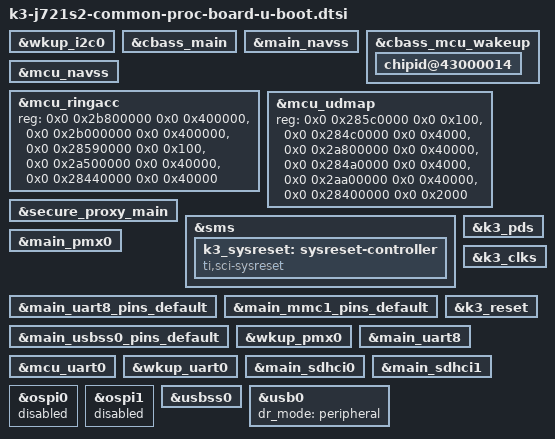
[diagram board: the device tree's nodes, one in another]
// SPDX-License-Identifier: GPL-2.0
/*
 * Copyright (C) 2021-2023 Texas Instruments Incorporated - https://www.ti.com/
 */

#include "k3-j721s2-binman.dtsi"

&wkup_i2c0 {
	bootph-pre-ram;
};

&cbass_main {
	bootph-pre-ram;
};

&main_navss {
	bootph-pre-ram;
};

&cbass_mcu_wakeup {
	bootph-pre-ram;

	chipid@43000014 {
		bootph-pre-ram;
	};
};

&mcu_navss {
	bootph-pre-ram;
};

&mcu_ringacc {
	reg =   <0x0 0x2b800000 0x0 0x400000>,
		<0x0 0x2b000000 0x0 0x400000>,
		<0x0 0x28590000 0x0 0x100>,
		<0x0 0x2a500000 0x0 0x40000>,
		<0x0 0x28440000 0x0 0x40000>;
	reg-names = "rt", "fifos", "proxy_gcfg", "proxy_target", "cfg";
	bootph-pre-ram;
};

&mcu_udmap {
	reg =   <0x0 0x285c0000 0x0 0x100>,
		<0x0 0x284c0000 0x0 0x4000>,
		<0x0 0x2a800000 0x0 0x40000>,
		<0x0 0x284a0000 0x0 0x4000>,
		<0x0 0x2aa00000 0x0 0x40000>,
		<0x0 0x28400000 0x0 0x2000>;
	reg-names = "gcfg", "rchan", "rchanrt", "tchan",
		    "tchanrt", "rflow";
	bootph-pre-ram;
};

&secure_proxy_main {
	bootph-pre-ram;
};

&sms {
	bootph-pre-ram;
	k3_sysreset: sysreset-controller {
		compatible = "ti,sci-sysreset";
		bootph-pre-ram;
	};
};

&main_pmx0 {
	bootph-pre-ram;
};

&main_uart8_pins_default {
	bootph-pre-ram;
};

&main_mmc1_pins_default {
	bootph-pre-ram;
};

&main_usbss0_pins_default {
	bootph-pre-ram;
};

&wkup_pmx0 {
	bootph-pre-ram;
};

&k3_pds {
	bootph-pre-ram;
};

&k3_clks {
	bootph-pre-ram;
};

&k3_reset {
	bootph-pre-ram;
};

&main_uart8 {
	bootph-pre-ram;
};

&mcu_uart0 {
	bootph-pre-ram;
};

&wkup_uart0 {
	bootph-pre-ram;
};

&main_sdhci0 {
	bootph-pre-ram;
};

&main_sdhci1 {
	bootph-pre-ram;
};

&ospi0 {
	status = "disabled";
};

&ospi1 {
	status = "disabled";
};

&usbss0 {
	bootph-pre-ram;
};

&usb0 {
	dr_mode = "peripheral";
	bootph-pre-ram;
};
